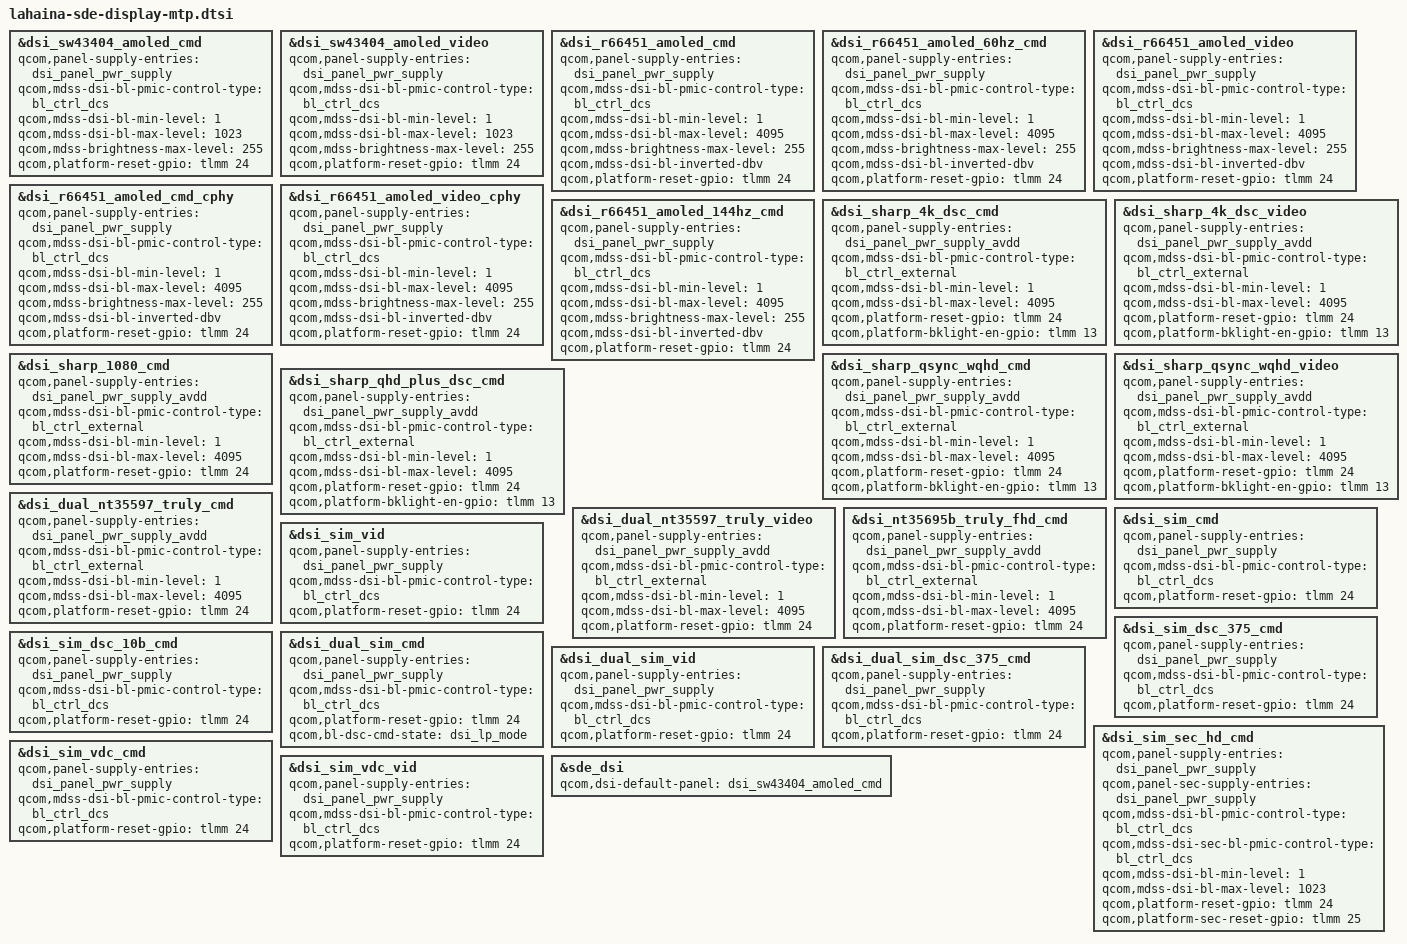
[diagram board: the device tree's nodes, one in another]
#include "lahaina-sde-display.dtsi"

&dsi_sw43404_amoled_cmd {
	qcom,panel-supply-entries = <&dsi_panel_pwr_supply>;
	qcom,mdss-dsi-bl-pmic-control-type = "bl_ctrl_dcs";
	qcom,mdss-dsi-bl-min-level = <1>;
	qcom,mdss-dsi-bl-max-level = <1023>;
	qcom,mdss-brightness-max-level = <255>;
	qcom,platform-reset-gpio = <&tlmm 24 0>;
};

&dsi_sw43404_amoled_video {
	qcom,panel-supply-entries = <&dsi_panel_pwr_supply>;
	qcom,mdss-dsi-bl-pmic-control-type = "bl_ctrl_dcs";
	qcom,mdss-dsi-bl-min-level = <1>;
	qcom,mdss-dsi-bl-max-level = <1023>;
	qcom,mdss-brightness-max-level = <255>;
	qcom,platform-reset-gpio = <&tlmm 24 0>;
};

&dsi_r66451_amoled_cmd {
	qcom,panel-supply-entries = <&dsi_panel_pwr_supply>;
	qcom,mdss-dsi-bl-pmic-control-type = "bl_ctrl_dcs";
	qcom,mdss-dsi-bl-min-level = <1>;
	qcom,mdss-dsi-bl-max-level = <4095>;
	qcom,mdss-brightness-max-level = <255>;
	qcom,mdss-dsi-bl-inverted-dbv;
	qcom,platform-reset-gpio = <&tlmm 24 0>;
};

&dsi_r66451_amoled_60hz_cmd {
	qcom,panel-supply-entries = <&dsi_panel_pwr_supply>;
	qcom,mdss-dsi-bl-pmic-control-type = "bl_ctrl_dcs";
	qcom,mdss-dsi-bl-min-level = <1>;
	qcom,mdss-dsi-bl-max-level = <4095>;
	qcom,mdss-brightness-max-level = <255>;
	qcom,mdss-dsi-bl-inverted-dbv;
	qcom,platform-reset-gpio = <&tlmm 24 0>;
};

&dsi_r66451_amoled_video {
	qcom,panel-supply-entries = <&dsi_panel_pwr_supply>;
	qcom,mdss-dsi-bl-pmic-control-type = "bl_ctrl_dcs";
	qcom,mdss-dsi-bl-min-level = <1>;
	qcom,mdss-dsi-bl-max-level = <4095>;
	qcom,mdss-brightness-max-level = <255>;
	qcom,mdss-dsi-bl-inverted-dbv;
	qcom,platform-reset-gpio = <&tlmm 24 0>;
};

&dsi_r66451_amoled_cmd_cphy {
	qcom,panel-supply-entries = <&dsi_panel_pwr_supply>;
	qcom,mdss-dsi-bl-pmic-control-type = "bl_ctrl_dcs";
	qcom,mdss-dsi-bl-min-level = <1>;
	qcom,mdss-dsi-bl-max-level = <4095>;
	qcom,mdss-brightness-max-level = <255>;
	qcom,mdss-dsi-bl-inverted-dbv;
	qcom,platform-reset-gpio = <&tlmm 24 0>;
};

&dsi_r66451_amoled_video_cphy {
	qcom,panel-supply-entries = <&dsi_panel_pwr_supply>;
	qcom,mdss-dsi-bl-pmic-control-type = "bl_ctrl_dcs";
	qcom,mdss-dsi-bl-min-level = <1>;
	qcom,mdss-dsi-bl-max-level = <4095>;
	qcom,mdss-brightness-max-level = <255>;
	qcom,mdss-dsi-bl-inverted-dbv;
	qcom,platform-reset-gpio = <&tlmm 24 0>;
};

&dsi_r66451_amoled_144hz_cmd {
	qcom,panel-supply-entries = <&dsi_panel_pwr_supply>;
	qcom,mdss-dsi-bl-pmic-control-type = "bl_ctrl_dcs";
	qcom,mdss-dsi-bl-min-level = <1>;
	qcom,mdss-dsi-bl-max-level = <4095>;
	qcom,mdss-brightness-max-level = <255>;
	qcom,mdss-dsi-bl-inverted-dbv;
	qcom,platform-reset-gpio = <&tlmm 24 0>;
};

&dsi_sharp_4k_dsc_cmd {
	qcom,panel-supply-entries = <&dsi_panel_pwr_supply_avdd>;
	qcom,mdss-dsi-bl-pmic-control-type = "bl_ctrl_external";
	qcom,mdss-dsi-bl-min-level = <1>;
	qcom,mdss-dsi-bl-max-level = <4095>;
	qcom,platform-reset-gpio = <&tlmm 24 0>;
	qcom,platform-bklight-en-gpio = <&tlmm 13 0>;
};

&dsi_sharp_4k_dsc_video {
	qcom,panel-supply-entries = <&dsi_panel_pwr_supply_avdd>;
	qcom,mdss-dsi-bl-pmic-control-type = "bl_ctrl_external";
	qcom,mdss-dsi-bl-min-level = <1>;
	qcom,mdss-dsi-bl-max-level = <4095>;
	qcom,platform-reset-gpio = <&tlmm 24 0>;
	qcom,platform-bklight-en-gpio = <&tlmm 13 0>;
};

&dsi_sharp_1080_cmd {
	qcom,panel-supply-entries = <&dsi_panel_pwr_supply_avdd>;
	qcom,mdss-dsi-bl-pmic-control-type = "bl_ctrl_external";
	qcom,mdss-dsi-bl-min-level = <1>;
	qcom,mdss-dsi-bl-max-level = <4095>;
	qcom,platform-reset-gpio = <&tlmm 24 0>;
};

&dsi_sharp_qsync_wqhd_cmd {
	qcom,panel-supply-entries = <&dsi_panel_pwr_supply_avdd>;
	qcom,mdss-dsi-bl-pmic-control-type = "bl_ctrl_external";
	qcom,mdss-dsi-bl-min-level = <1>;
	qcom,mdss-dsi-bl-max-level = <4095>;
	qcom,platform-reset-gpio = <&tlmm 24 0>;
	qcom,platform-bklight-en-gpio = <&tlmm 13 0>;
};

&dsi_sharp_qsync_wqhd_video {
	qcom,panel-supply-entries = <&dsi_panel_pwr_supply_avdd>;
	qcom,mdss-dsi-bl-pmic-control-type = "bl_ctrl_external";
	qcom,mdss-dsi-bl-min-level = <1>;
	qcom,mdss-dsi-bl-max-level = <4095>;
	qcom,platform-reset-gpio = <&tlmm 24 0>;
	qcom,platform-bklight-en-gpio = <&tlmm 13 0>;
};

&dsi_sharp_qhd_plus_dsc_cmd {
	qcom,panel-supply-entries = <&dsi_panel_pwr_supply_avdd>;
	qcom,mdss-dsi-bl-pmic-control-type = "bl_ctrl_external";
	qcom,mdss-dsi-bl-min-level = <1>;
	qcom,mdss-dsi-bl-max-level = <4095>;
	qcom,platform-reset-gpio = <&tlmm 24 0>;
	qcom,platform-bklight-en-gpio = <&tlmm 13 0>;
};

&dsi_dual_nt35597_truly_cmd {
	qcom,panel-supply-entries = <&dsi_panel_pwr_supply_avdd>;
	qcom,mdss-dsi-bl-pmic-control-type = "bl_ctrl_external";
	qcom,mdss-dsi-bl-min-level = <1>;
	qcom,mdss-dsi-bl-max-level = <4095>;
	qcom,platform-reset-gpio = <&tlmm 24 0>;
};

&dsi_dual_nt35597_truly_video {
	qcom,panel-supply-entries = <&dsi_panel_pwr_supply_avdd>;
	qcom,mdss-dsi-bl-pmic-control-type = "bl_ctrl_external";
	qcom,mdss-dsi-bl-min-level = <1>;
	qcom,mdss-dsi-bl-max-level = <4095>;
	qcom,platform-reset-gpio = <&tlmm 24 0>;
};

&dsi_nt35695b_truly_fhd_cmd {
	qcom,panel-supply-entries = <&dsi_panel_pwr_supply_avdd>;
	qcom,mdss-dsi-bl-pmic-control-type = "bl_ctrl_external";
	qcom,mdss-dsi-bl-min-level = <1>;
	qcom,mdss-dsi-bl-max-level = <4095>;
	qcom,platform-reset-gpio = <&tlmm 24 0>;
};

&dsi_sim_cmd {
	qcom,panel-supply-entries = <&dsi_panel_pwr_supply>;
	qcom,mdss-dsi-bl-pmic-control-type = "bl_ctrl_dcs";
	qcom,platform-reset-gpio = <&tlmm 24 0>;
};

&dsi_sim_vid {
	qcom,panel-supply-entries = <&dsi_panel_pwr_supply>;
	qcom,mdss-dsi-bl-pmic-control-type = "bl_ctrl_dcs";
	qcom,platform-reset-gpio = <&tlmm 24 0>;
};

&dsi_sim_dsc_375_cmd {
	qcom,panel-supply-entries = <&dsi_panel_pwr_supply>;
	qcom,mdss-dsi-bl-pmic-control-type = "bl_ctrl_dcs";
	qcom,platform-reset-gpio = <&tlmm 24 0>;
};

&dsi_sim_dsc_10b_cmd {
	qcom,panel-supply-entries = <&dsi_panel_pwr_supply>;
	qcom,mdss-dsi-bl-pmic-control-type = "bl_ctrl_dcs";
	qcom,platform-reset-gpio = <&tlmm 24 0>;
};

&dsi_dual_sim_cmd {
	qcom,panel-supply-entries = <&dsi_panel_pwr_supply>;
	qcom,mdss-dsi-bl-pmic-control-type = "bl_ctrl_dcs";
	qcom,platform-reset-gpio = <&tlmm 24 0>;
	qcom,bl-dsc-cmd-state = "dsi_lp_mode";
};

&dsi_dual_sim_vid {
	qcom,panel-supply-entries = <&dsi_panel_pwr_supply>;
	qcom,mdss-dsi-bl-pmic-control-type = "bl_ctrl_dcs";
	qcom,platform-reset-gpio = <&tlmm 24 0>;
};

&dsi_dual_sim_dsc_375_cmd {
	qcom,panel-supply-entries = <&dsi_panel_pwr_supply>;
	qcom,mdss-dsi-bl-pmic-control-type = "bl_ctrl_dcs";
	qcom,platform-reset-gpio = <&tlmm 24 0>;
};

&dsi_sim_sec_hd_cmd {
	qcom,panel-supply-entries = <&dsi_panel_pwr_supply>;
	qcom,panel-sec-supply-entries = <&dsi_panel_pwr_supply>;
	qcom,mdss-dsi-bl-pmic-control-type = "bl_ctrl_dcs";
	qcom,mdss-dsi-sec-bl-pmic-control-type = "bl_ctrl_dcs";
	qcom,mdss-dsi-bl-min-level = <1>;
	qcom,mdss-dsi-bl-max-level = <1023>;
	qcom,platform-reset-gpio = <&tlmm 24 0>;
	qcom,platform-sec-reset-gpio = <&tlmm 25 0>;
};

&dsi_sim_vdc_cmd {
	qcom,panel-supply-entries = <&dsi_panel_pwr_supply>;
	qcom,mdss-dsi-bl-pmic-control-type = "bl_ctrl_dcs";
	qcom,platform-reset-gpio = <&tlmm 24 0>;
};

&dsi_sim_vdc_vid {
	qcom,panel-supply-entries = <&dsi_panel_pwr_supply>;
	qcom,mdss-dsi-bl-pmic-control-type = "bl_ctrl_dcs";
	qcom,platform-reset-gpio = <&tlmm 24 0>;
};

&sde_dsi {
	qcom,dsi-default-panel = <&dsi_sw43404_amoled_cmd>;
};
